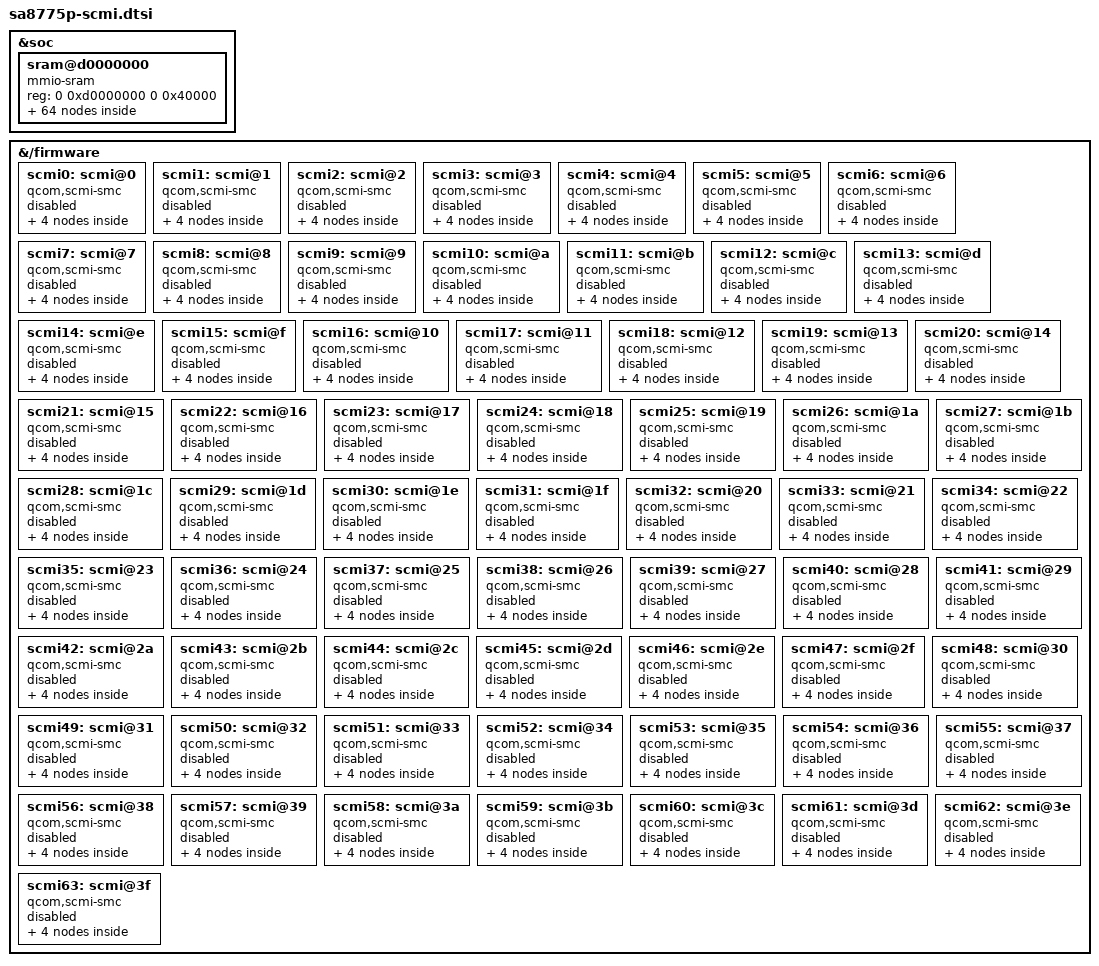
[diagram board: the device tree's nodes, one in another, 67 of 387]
/*
 * Copyright (c) 2023 Qualcomm Innovation Center, Inc. All rights reserved.
 * SPDX-License-Identifier: BSD-3-Clause
 */

&soc {
	sram@d0000000 {
		#address-cells = <2>;
		#size-cells = <2>;
		compatible = "mmio-sram";
		reg = <0 0xd0000000 0 0x40000>;
		ranges;

		shmem0: scmi-sram@d0000000 {
			compatible = "arm,scmi-shmem";
			reg = <0 0xd0000000 0 0x1000>;
		};

		shmem1: scmi-sram@d0001000 {
			compatible = "arm,scmi-shmem";
			reg = <0 0xd0001000 0 0x1000>;
		};

		shmem2: scmi-sram@d0002000 {
			compatible = "arm,scmi-shmem";
			reg = <0 0xd0002000 0 0x1000>;
		};

		shmem3: scmi-sram@d0003000 {
			compatible = "arm,scmi-shmem";
			reg = <0 0xd0003000 0 0x1000>;
		};

		shmem4: scmi-sram@d0004000 {
			compatible = "arm,scmi-shmem";
			reg = <0 0xd0004000 0 0x1000>;
		};

		shmem5: scmi-sram@d0005000 {
			compatible = "arm,scmi-shmem";
			reg = <0 0xd0005000 0 0x1000>;
		};

		shmem6: scmi-sram@d0006000 {
			compatible = "arm,scmi-shmem";
			reg = <0 0xd0006000 0 0x1000>;
		};

		shmem7: scmi-sram@d0007000 {
			compatible = "arm,scmi-shmem";
			reg = <0 0xd0007000 0 0x1000>;
		};

		shmem8: scmi-sram@d0008000 {
			compatible = "arm,scmi-shmem";
			reg = <0 0xd0008000 0 0x1000>;
		};

		shmem9: scmi-sram@d0009000 {
			compatible = "arm,scmi-shmem";
			reg = <0 0xd0009000 0 0x1000>;
		};

		shmem10: scmi-sram@d000a000 {
			compatible = "arm,scmi-shmem";
			reg = <0 0xd000a000 0 0x1000>;
		};

		shmem11: scmi-sram@d000b000 {
			compatible = "arm,scmi-shmem";
			reg = <0 0xd000b000 0 0x1000>;
		};

		shmem12: scmi-sram@d000c000 {
			compatible = "arm,scmi-shmem";
			reg = <0 0xd000c000 0 0x1000>;
		};

		shmem13: scmi-sram@d000d000 {
			compatible = "arm,scmi-shmem";
			reg = <0 0xd000d000 0 0x1000>;
		};

		shmem14: scmi-sram@d000e000 {
			compatible = "arm,scmi-shmem";
			reg = <0 0xd000e000 0 0x1000>;
		};

		shmem15: scmi-sram@d000f000 {
			compatible = "arm,scmi-shmem";
			reg = <0 0xd000f000 0 0x1000>;
		};

		shmem16: scmi-sram@d0010000 {
			compatible = "arm,scmi-shmem";
			reg = <0 0xd0010000 0 0x1000>;
		};

		shmem17: scmi-sram@d0011000 {
			compatible = "arm,scmi-shmem";
			reg = <0 0xd0011000 0 0x1000>;
		};

		shmem18: scmi-sram@d0012000 {
			compatible = "arm,scmi-shmem";
			reg = <0 0xd0012000 0 0x1000>;
		};

		shmem19: scmi-sram@d0013000 {
			compatible = "arm,scmi-shmem";
			reg = <0 0xd0013000 0 0x1000>;
		};

		shmem20: scmi-sram@d0014000 {
			compatible = "arm,scmi-shmem";
			reg = <0 0xd0014000 0 0x1000>;
		};

		shmem21: scmi-sram@d0015000 {
			compatible = "arm,scmi-shmem";
			reg = <0 0xd0015000 0 0x1000>;
		};

		shmem22: scmi-sram@d0016000 {
			compatible = "arm,scmi-shmem";
			reg = <0 0xd0016000 0 0x1000>;
		};

		shmem23: scmi-sram@d0017000 {
			compatible = "arm,scmi-shmem";
			reg = <0 0xd0017000 0 0x1000>;
		};

		shmem24: scmi-sram@d0018000 {
			compatible = "arm,scmi-shmem";
			reg = <0 0xd0018000 0 0x1000>;
		};

		shmem25: scmi-sram@d0019000 {
			compatible = "arm,scmi-shmem";
			reg = <0 0xd0019000 0 0x1000>;
		};

		shmem26: scmi-sram@d001a000 {
			compatible = "arm,scmi-shmem";
			reg = <0 0xd001a000 0 0x1000>;
		};

		shmem27: scmi-sram@d001b000 {
			compatible = "arm,scmi-shmem";
			reg = <0 0xd001b000 0 0x1000>;
		};

		shmem28: scmi-sram@d001c000 {
			compatible = "arm,scmi-shmem";
			reg = <0 0xd001c000 0 0x1000>;
		};

		shmem29: scmi-sram@d001d000 {
			compatible = "arm,scmi-shmem";
			reg = <0 0xd001d000 0 0x1000>;
		};

		shmem30: scmi-sram@d001e000 {
			compatible = "arm,scmi-shmem";
			reg = <0 0xd001e000 0 0x1000>;
		};

		shmem31: scmi-sram@d001f000 {
			compatible = "arm,scmi-shmem";
			reg = <0 0xd001f000 0 0x1000>;
		};

		shmem32: scmi-sram@d0020000 {
			compatible = "arm,scmi-shmem";
			reg = <0 0xd0020000 0 0x1000>;
		};

		shmem33: scmi-sram@d0021000 {
			compatible = "arm,scmi-shmem";
			reg = <0 0xd0021000 0 0x1000>;
		};

		shmem34: scmi-sram@d0022000 {
			compatible = "arm,scmi-shmem";
			reg = <0 0xd0022000 0 0x1000>;
		};

		shmem35: scmi-sram@d0023000 {
			compatible = "arm,scmi-shmem";
			reg = <0 0xd0023000 0 0x1000>;
		};

		shmem36: scmi-sram@d0024000 {
			compatible = "arm,scmi-shmem";
			reg = <0 0xd0024000 0 0x1000>;
		};

		shmem37: scmi-sram@d0025000 {
			compatible = "arm,scmi-shmem";
			reg = <0 0xd0025000 0 0x1000>;
		};

		shmem38: scmi-sram@d0026000 {
			compatible = "arm,scmi-shmem";
			reg = <0 0xd0026000 0 0x1000>;
		};

		shmem39: scmi-sram@d0027000 {
			compatible = "arm,scmi-shmem";
			reg = <0 0xd0027000 0 0x1000>;
		};

		shmem40: scmi-sram@d0028000 {
			compatible = "arm,scmi-shmem";
			reg = <0 0xd0028000 0 0x1000>;
		};

		shmem41: scmi-sram@d0029000 {
			compatible = "arm,scmi-shmem";
			reg = <0 0xd0029000 0 0x1000>;
		};

		shmem42: scmi-sram@d002a000 {
			compatible = "arm,scmi-shmem";
			reg = <0 0xd002a000 0 0x1000>;
		};

		shmem43: scmi-sram@d002b000 {
			compatible = "arm,scmi-shmem";
			reg = <0 0xd002b000 0 0x1000>;
		};

		shmem44: scmi-sram@d002c000 {
			compatible = "arm,scmi-shmem";
			reg = <0 0xd002c000 0 0x1000>;
		};

		shmem45: scmi-sram@d002d000 {
			compatible = "arm,scmi-shmem";
			reg = <0 0xd002d000 0 0x1000>;
		};

		shmem46: scmi-sram@d002e000 {
			compatible = "arm,scmi-shmem";
			reg = <0 0xd002e000 0 0x1000>;
		};

		shmem47: scmi-sram@d002f000 {
			compatible = "arm,scmi-shmem";
			reg = <0 0xd002f000 0 0x1000>;
		};

		shmem48: scmi-sram@d0030000 {
			compatible = "arm,scmi-shmem";
			reg = <0 0xd0030000 0 0x1000>;
		};

		shmem49: scmi-sram@d0031000 {
			compatible = "arm,scmi-shmem";
			reg = <0 0xd0031000 0 0x1000>;
		};

		shmem50: scmi-sram@d0032000 {
			compatible = "arm,scmi-shmem";
			reg = <0 0xd0032000 0 0x1000>;
		};

		shmem51: scmi-sram@d0033000 {
			compatible = "arm,scmi-shmem";
			reg = <0 0xd0033000 0 0x1000>;
		};

		shmem52: scmi-sram@d0034000 {
			compatible = "arm,scmi-shmem";
			reg = <0 0xd0034000 0 0x1000>;
		};

		shmem53: scmi-sram@d0035000 {
			compatible = "arm,scmi-shmem";
			reg = <0 0xd0035000 0 0x1000>;
		};

		shmem54: scmi-sram@d0036000 {
			compatible = "arm,scmi-shmem";
			reg = <0 0xd0036000 0 0x1000>;
		};

		shmem55: scmi-sram@d0037000 {
			compatible = "arm,scmi-shmem";
			reg = <0 0xd0037000 0 0x1000>;
		};

		shmem56: scmi-sram@d0038000 {
			compatible = "arm,scmi-shmem";
			reg = <0 0xd0038000 0 0x1000>;
		};

		shmem57: scmi-sram@d0039000 {
			compatible = "arm,scmi-shmem";
			reg = <0 0xd0039000 0 0x1000>;
		};

		shmem58: scmi-sram@d003a000 {
			compatible = "arm,scmi-shmem";
			reg = <0 0xd003a000 0 0x1000>;
		};

		shmem59: scmi-sram@d003b000 {
			compatible = "arm,scmi-shmem";
			reg = <0 0xd003b000 0 0x1000>;
		};

		shmem60: scmi-sram@d003c000 {
			compatible = "arm,scmi-shmem";
			reg = <0 0xd003c000 0 0x1000>;
		};

		shmem61: scmi-sram@d003d000 {
			compatible = "arm,scmi-shmem";
			reg = <0 0xd003d000 0 0x1000>;
		};

		shmem62: scmi-sram@d003e000 {
			compatible = "arm,scmi-shmem";
			reg = <0 0xd003e000 0 0x1000>;
		};

		shmem63: scmi-sram@d003f000 {
			compatible = "arm,scmi-shmem";
			reg = <0 0xd003f000 0 0x1000>;
		};
	};
};

&{/firmware} {
	scmi0: scmi@0 {
		compatible = "qcom,scmi-smc";
		arm,smc-id = <0xc6008012>;
		shmem = <&shmem0>;

		interrupts = <GIC_SPI 920 IRQ_TYPE_EDGE_RISING>;
		interrupt-names = "a2p";

		status = "disabled";

		#address-cells = <1>;
		#size-cells = <0>;

		scmi0_pd: protocol@11 {
			reg = <0x11>;
			#power-domain-cells = <1>;
			status = "disabled";
		};

		scmi0_dvfs: protocol@13 {
			reg = <0x13>;
			#power-domain-cells = <1>;
			status = "disabled";
		};

		scmi0_sensor: protocol@15 {
			reg = <0x15>;
			#thermal-sensor-cells = <1>;
			status = "disabled";
		};

		scmi0_rst: protocol@16 {
			reg = <0x16>;
			#reset-cells = <1>;
			status = "disabled";
		};
	};

	scmi1: scmi@1 {
		compatible = "qcom,scmi-smc";
		arm,smc-id = <0xc6008012>;
		shmem = <&shmem1>;

		interrupts = <GIC_SPI 921 IRQ_TYPE_EDGE_RISING>;
		interrupt-names = "a2p";

		status = "disabled";

		#address-cells = <1>;
		#size-cells = <0>;

		scmi1_pd: protocol@11 {
			reg = <0x11>;
			#power-domain-cells = <1>;
			status = "disabled";
		};

		scmi1_dvfs: protocol@13 {
			reg = <0x13>;
			#power-domain-cells = <1>;
			status = "disabled";
		};

		scmi1_sensor: protocol@15 {
			reg = <0x15>;
			#thermal-sensor-cells = <1>;
			status = "disabled";
		};

		scmi1_rst: protocol@16 {
			reg = <0x16>;
			#reset-cells = <1>;
			status = "disabled";
		};
	};

	scmi2: scmi@2 {
		compatible = "qcom,scmi-smc";
		arm,smc-id = <0xc6008012>;
		shmem = <&shmem2>;

		interrupts = <GIC_SPI 922 IRQ_TYPE_EDGE_RISING>;
		interrupt-names = "a2p";

		status = "disabled";

		#address-cells = <1>;
		#size-cells = <0>;

		scmi2_pd: protocol@11 {
			reg = <0x11>;
			#power-domain-cells = <1>;
			status = "disabled";
		};

		scmi2_dvfs: protocol@13 {
			reg = <0x13>;
			#power-domain-cells = <1>;
			status = "disabled";
		};

		scmi2_sensor: protocol@15 {
			reg = <0x15>;
			#thermal-sensor-cells = <1>;
			status = "disabled";
		};

		scmi2_rst: protocol@16 {
			reg = <0x16>;
			#reset-cells = <1>;
			status = "disabled";
		};
	};

	scmi3: scmi@3 {
		compatible = "qcom,scmi-smc";
		arm,smc-id = <0xc6008012>;
		shmem = <&shmem3>;

		interrupts = <GIC_SPI 923 IRQ_TYPE_EDGE_RISING>;
		interrupt-names = "a2p";

		status = "disabled";

		#address-cells = <1>;
		#size-cells = <0>;

		scmi3_pd: protocol@11 {
			reg = <0x11>;
			#power-domain-cells = <1>;
			status = "disabled";
		};

		scmi3_dvfs: protocol@13 {
			reg = <0x13>;
			#power-domain-cells = <1>;
			status = "disabled";
		};

		scmi3_sensor: protocol@15 {
			reg = <0x15>;
			#thermal-sensor-cells = <1>;
			status = "disabled";
		};

		scmi3_rst: protocol@16 {
			reg = <0x16>;
			#reset-cells = <1>;
			status = "disabled";
		};
	};

	scmi4: scmi@4 {
		compatible = "qcom,scmi-smc";
		arm,smc-id = <0xc6008012>;
		shmem = <&shmem4>;

		interrupts = <GIC_SPI 924 IRQ_TYPE_EDGE_RISING>;
		interrupt-names = "a2p";

		status = "disabled";

		#address-cells = <1>;
		#size-cells = <0>;

		scmi4_pd: protocol@11 {
			reg = <0x11>;
			#power-domain-cells = <1>;
			status = "disabled";
		};

		scmi4_dvfs: protocol@13 {
			reg = <0x13>;
			#power-domain-cells = <1>;
			status = "disabled";
		};

		scmi4_sensor: protocol@15 {
			reg = <0x15>;
			#thermal-sensor-cells = <1>;
			status = "disabled";
		};

		scmi4_rst: protocol@16 {
			reg = <0x16>;
			#reset-cells = <1>;
			status = "disabled";
		};
	};

	scmi5: scmi@5 {
		compatible = "qcom,scmi-smc";
		arm,smc-id = <0xc6008012>;
		shmem = <&shmem5>;

		interrupts = <GIC_SPI 925 IRQ_TYPE_EDGE_RISING>;
		interrupt-names = "a2p";

		status = "disabled";

		#address-cells = <1>;
		#size-cells = <0>;

		scmi5_pd: protocol@11 {
			reg = <0x11>;
			#power-domain-cells = <1>;
			status = "disabled";
		};

		scmi5_dvfs: protocol@13 {
			reg = <0x13>;
			#power-domain-cells = <1>;
			status = "disabled";
		};

		scmi5_sensor: protocol@15 {
			reg = <0x15>;
			#thermal-sensor-cells = <1>;
			status = "disabled";
		};

		scmi5_rst: protocol@16 {
			reg = <0x16>;
			#reset-cells = <1>;
			status = "disabled";
		};
	};

	scmi6: scmi@6 {
		compatible = "qcom,scmi-smc";
		arm,smc-id = <0xc6008012>;
		shmem = <&shmem6>;

		interrupts = <GIC_SPI 926 IRQ_TYPE_EDGE_RISING>;
		interrupt-names = "a2p";

		status = "disabled";

		#address-cells = <1>;
		#size-cells = <0>;

		scmi6_pd: protocol@11 {
			reg = <0x11>;
			#power-domain-cells = <1>;
			status = "disabled";
		};

		scmi6_dvfs: protocol@13 {
			reg = <0x13>;
			#power-domain-cells = <1>;
			status = "disabled";
		};

		scmi6_sensor: protocol@15 {
			reg = <0x15>;
			#thermal-sensor-cells = <1>;
			status = "disabled";
		};

		scmi6_rst: protocol@16 {
			reg = <0x16>;
			#reset-cells = <1>;
			status = "disabled";
		};
	};

	scmi7: scmi@7 {
		compatible = "qcom,scmi-smc";
		arm,smc-id = <0xc6008012>;
		shmem = <&shmem7>;

		interrupts = <GIC_SPI 927 IRQ_TYPE_EDGE_RISING>;
		interrupt-names = "a2p";

		status = "disabled";

		#address-cells = <1>;
		#size-cells = <0>;

		scmi7_pd: protocol@11 {
			reg = <0x11>;
			#power-domain-cells = <1>;
			status = "disabled";
		};

		scmi7_dvfs: protocol@13 {
			reg = <0x13>;
			#power-domain-cells = <1>;
			status = "disabled";
		};

		scmi7_sensor: protocol@15 {
			reg = <0x15>;
			#thermal-sensor-cells = <1>;
			status = "disabled";
		};

		scmi7_rst: protocol@16 {
			reg = <0x16>;
			#reset-cells = <1>;
			status = "disabled";
		};
	};

	scmi8: scmi@8 {
		compatible = "qcom,scmi-smc";
		arm,smc-id = <0xc6008012>;
		shmem = <&shmem8>;

		interrupts = <GIC_SPI 928 IRQ_TYPE_EDGE_RISING>;
		interrupt-names = "a2p";

		status = "disabled";

		#address-cells = <1>;
		#size-cells = <0>;

		scmi8_pd: protocol@11 {
			reg = <0x11>;
			#power-domain-cells = <1>;
			status = "disabled";
		};

		scmi8_dvfs: protocol@13 {
			reg = <0x13>;
			#power-domain-cells = <1>;
			status = "disabled";
		};

		scmi8_sensor: protocol@15 {
			reg = <0x15>;
			#thermal-sensor-cells = <1>;
			status = "disabled";
		};

		scmi8_rst: protocol@16 {
			reg = <0x16>;
			#reset-cells = <1>;
			status = "disabled";
		};
	};

	scmi9: scmi@9 {
		compatible = "qcom,scmi-smc";
		arm,smc-id = <0xc6008012>;
		shmem = <&shmem9>;

		interrupts = <GIC_SPI 929 IRQ_TYPE_EDGE_RISING>;
		interrupt-names = "a2p";

		status = "disabled";

		#address-cells = <1>;
		#size-cells = <0>;

		scmi9_pd: protocol@11 {
			reg = <0x11>;
			#power-domain-cells = <1>;
			status = "disabled";
		};

		scmi9_dvfs: protocol@13 {
			reg = <0x13>;
			#power-domain-cells = <1>;
			status = "disabled";
		};

		scmi9_sensor: protocol@15 {
			reg = <0x15>;
			#thermal-sensor-cells = <1>;
			status = "disabled";
		};

		scmi9_rst: protocol@16 {
			reg = <0x16>;
			#reset-cells = <1>;
			status = "disabled";
		};
	};

	scmi10: scmi@a {
		compatible = "qcom,scmi-smc";
		arm,smc-id = <0xc6008012>;
		shmem = <&shmem10>;

		interrupts = <GIC_SPI 930 IRQ_TYPE_EDGE_RISING>;
		interrupt-names = "a2p";

		status = "disabled";

		#address-cells = <1>;
		#size-cells = <0>;

		scmi10_pd: protocol@11 {
			reg = <0x11>;
			#power-domain-cells = <1>;
			status = "disabled";
		};

		scmi10_dvfs: protocol@13 {
			reg = <0x13>;
			#power-domain-cells = <1>;
			status = "disabled";
		};

		scmi10_sensor: protocol@15 {
			reg = <0x15>;
			#thermal-sensor-cells = <1>;
			status = "disabled";
		};

		scmi10_rst: protocol@16 {
			reg = <0x16>;
			#reset-cells = <1>;
			status = "disabled";
		};
	};

	scmi11: scmi@b {
		compatible = "qcom,scmi-smc";
		arm,smc-id = <0xc6008012>;
		shmem = <&shmem11>;

		interrupts = <GIC_SPI 931 IRQ_TYPE_EDGE_RISING>;
		interrupt-names = "a2p";

		status = "disabled";

		#address-cells = <1>;
		#size-cells = <0>;

		scmi11_pd: protocol@11 {
			reg = <0x11>;
			#power-domain-cells = <1>;
			status = "disabled";
		};

		scmi11_dvfs: protocol@13 {
			reg = <0x13>;
			#power-domain-cells = <1>;
			status = "disabled";
		};

		scmi11_sensor: protocol@15 {
			reg = <0x15>;
			#thermal-sensor-cells = <1>;
			status = "disabled";
		};

		scmi11_rst: protocol@16 {
			reg = <0x16>;
			#reset-cells = <1>;
			status = "disabled";
		};
	};

	scmi12: scmi@c {
		compatible = "qcom,scmi-smc";
		arm,smc-id = <0xc6008012>;
		shmem = <&shmem12>;

		interrupts = <GIC_SPI 932 IRQ_TYPE_EDGE_RISING>;
		interrupt-names = "a2p";

		status = "disabled";

		#address-cells = <1>;
		#size-cells = <0>;

		scmi12_pd: protocol@11 {
			reg = <0x11>;
			#power-domain-cells = <1>;
			status = "disabled";
		};

		scmi12_dvfs: protocol@13 {
			reg = <0x13>;
			#power-domain-cells = <1>;
			status = "disabled";
		};

		scmi12_sensor: protocol@15 {
			reg = <0x15>;
			#thermal-sensor-cells = <1>;
			status = "disabled";
		};

		scmi12_rst: protocol@16 {
			reg = <0x16>;
			#reset-cells = <1>;
			status = "disabled";
		};
	};

	scmi13: scmi@d {
		compatible = "qcom,scmi-smc";
		arm,smc-id = <0xc6008012>;
		shmem = <&shmem13>;

		interrupts = <GIC_SPI 933 IRQ_TYPE_EDGE_RISING>;
		interrupt-names = "a2p";

		status = "disabled";

		#address-cells = <1>;
		#size-cells = <0>;

		scmi13_pd: protocol@11 {
			reg = <0x11>;
			#power-domain-cells = <1>;
			status = "disabled";
		};

		scmi13_dvfs: protocol@13 {
			reg = <0x13>;
			#power-domain-cells = <1>;
			status = "disabled";
		};

		scmi13_sensor: protocol@15 {
			reg = <0x15>;
			#thermal-sensor-cells = <1>;
			status = "disabled";
		};

		scmi13_rst: protocol@16 {
			reg = <0x16>;
			#reset-cells = <1>;
			status = "disabled";
		};
	};

	scmi14: scmi@e {
		compatible = "qcom,scmi-smc";
		arm,smc-id = <0xc6008012>;
		shmem = <&shmem14>;

		interrupts = <GIC_SPI 934 IRQ_TYPE_EDGE_RISING>;
		interrupt-names = "a2p";

		status = "disabled";

		#address-cells = <1>;
		#size-cells = <0>;

		scmi14_pd: protocol@11 {
			reg = <0x11>;
			#power-domain-cells = <1>;
			status = "disabled";
		};

		scmi14_dvfs: protocol@13 {
			reg = <0x13>;
			#power-domain-cells = <1>;
			status = "disabled";
		};

		scmi14_sensor: protocol@15 {
			reg = <0x15>;
			#thermal-sensor-cells = <1>;
			status = "disabled";
		};

		scmi14_rst: protocol@16 {
			reg = <0x16>;
			#reset-cells = <1>;
			status = "disabled";
		};
	};

	scmi15: scmi@f {
		compatible = "qcom,scmi-smc";
		arm,smc-id = <0xc6008012>;
		shmem = <&shmem15>;

		interrupts = <GIC_SPI 935 IRQ_TYPE_EDGE_RISING>;
		interrupt-names = "a2p";

		status = "disabled";

		#address-cells = <1>;
		#size-cells = <0>;

		scmi15_pd: protocol@11 {
			reg = <0x11>;
			#power-domain-cells = <1>;
			status = "disabled";
		};

		scmi15_dvfs: protocol@13 {
			reg = <0x13>;
			#power-domain-cells = <1>;
			status = "disabled";
		};

		scmi15_sensor: protocol@15 {
			reg = <0x15>;
			#thermal-sensor-cells = <1>;
			status = "disabled";
		};

		scmi15_rst: protocol@16 {
			reg = <0x16>;
			#reset-cells = <1>;
			status = "disabled";
		};
	};

	scmi16: scmi@10 {
		compatible = "qcom,scmi-smc";
		arm,smc-id = <0xc6008012>;
		shmem = <&shmem16>;

		interrupts = <GIC_SPI 936 IRQ_TYPE_EDGE_RISING>;
		interrupt-names = "a2p";

		status = "disabled";

		#address-cells = <1>;
		#size-cells = <0>;

		scmi16_pd: protocol@11 {
			reg = <0x11>;
			#power-domain-cells = <1>;
			status = "disabled";
		};

		scmi16_dvfs: protocol@13 {
			reg = <0x13>;
			#power-domain-cells = <1>;
			status = "disabled";
		};

		scmi16_sensor: protocol@15 {
			reg = <0x15>;
			#thermal-sensor-cells = <1>;
			status = "disabled";
		};

		scmi16_rst: protocol@16 {
			reg = <0x16>;
			#reset-cells = <1>;
			status = "disabled";
		};
	};

	scmi17: scmi@11 {
		compatible = "qcom,scmi-smc";
		arm,smc-id = <0xc6008012>;
		shmem = <&shmem17>;

		interrupts = <GIC_SPI 937 IRQ_TYPE_EDGE_RISING>;
		interrupt-names = "a2p";

		status = "disabled";

		#address-cells = <1>;
		#size-cells = <0>;

		scmi17_pd: protocol@11 {
			reg = <0x11>;
			#power-domain-cells = <1>;
			status = "disabled";
		};

		scmi17_dvfs: protocol@13 {
			reg = <0x13>;
			#power-domain-cells = <1>;
			status = "disabled";
		};

		scmi17_sensor: protocol@15 {
			reg = <0x15>;
			#thermal-sensor-cells = <1>;
			status = "disabled";
		};

		scmi17_rst: protocol@16 {
			reg = <0x16>;
			#reset-cells = <1>;
			status = "disabled";
		};
	};

	scmi18: scmi@12 {
		compatible = "qcom,scmi-smc";
		arm,smc-id = <0xc6008012>;
		shmem = <&shmem18>;

		interrupts = <GIC_SPI 938 IRQ_TYPE_EDGE_RISING>;
		interrupt-names = "a2p";

		status = "disabled";

		#address-cells = <1>;
		#size-cells = <0>;

		scmi18_pd: protocol@11 {
			reg = <0x11>;
			#power-domain-cells = <1>;
			status = "disabled";
		};

		scmi18_dvfs: protocol@13 {
			reg = <0x13>;
			#power-domain-cells = <1>;
			status = "disabled";
		};

		scmi18_sensor: protocol@15 {
			reg = <0x15>;
			#thermal-sensor-cells = <1>;
			status = "disabled";
		};

		scmi18_rst: protocol@16 {
			reg = <0x16>;
			#reset-cells = <1>;
			status = "disabled";
		};
	};

	scmi19: scmi@13 {
		compatible = "qcom,scmi-smc";
		arm,smc-id = <0xc6008012>;
		shmem = <&shmem19>;

		interrupts = <GIC_SPI 939 IRQ_TYPE_EDGE_RISING>;
		interrupt-names = "a2p";

		status = "disabled";

		#address-cells = <1>;
		#size-cells = <0>;

		scmi19_pd: protocol@11 {
			reg = <0x11>;
			#power-domain-cells = <1>;
			status = "disabled";
		};

		scmi19_dvfs: protocol@13 {
			reg = <0x13>;
			#power-domain-cells = <1>;
			status = "disabled";
		};

		scmi19_sensor: protocol@15 {
			reg = <0x15>;
			#thermal-sensor-cells = <1>;
			status = "disabled";
		};

		scmi19_rst: protocol@16 {
			reg = <0x16>;
			#reset-cells = <1>;
			status = "disabled";
		};
	};

	scmi20: scmi@14 {
		compatible = "qcom,scmi-smc";
		arm,smc-id = <0xc6008012>;
		shmem = <&shmem20>;

		interrupts = <GIC_SPI 940 IRQ_TYPE_EDGE_RISING>;
		interrupt-names = "a2p";

		status = "disabled";

		#address-cells = <1>;
		#size-cells = <0>;

		scmi20_pd: protocol@11 {
			reg = <0x11>;
			#power-domain-cells = <1>;
			status = "disabled";
		};

		scmi20_dvfs: protocol@13 {
			reg = <0x13>;
			#power-domain-cells = <1>;
			status = "disabled";
		};

		scmi20_sensor: protocol@15 {
			reg = <0x15>;
			#thermal-sensor-cells = <1>;
			status = "disabled";
		};

		scmi20_rst: protocol@16 {
			reg = <0x16>;
			#reset-cells = <1>;
			status = "disabled";
		};
	};

	scmi21: scmi@15 {
		compatible = "qcom,scmi-smc";
		arm,smc-id = <0xc6008012>;
		shmem = <&shmem21>;

		interrupts = <GIC_SPI 941 IRQ_TYPE_EDGE_RISING>;
		interrupt-names = "a2p";

		status = "disabled";

		#address-cells = <1>;
		#size-cells = <0>;

		scmi21_pd: protocol@11 {
			reg = <0x11>;
			#power-domain-cells = <1>;
			status = "disabled";
		};

		scmi21_dvfs: protocol@13 {
			reg = <0x13>;
			#power-domain-cells = <1>;
			status = "disabled";
		};

		scmi21_sensor: protocol@15 {
			reg = <0x15>;
			#thermal-sensor-cells = <1>;
			status = "disabled";
		};

		scmi21_rst: protocol@16 {
			reg = <0x16>;
			#reset-cells = <1>;
			status = "disabled";
		};
	};

	scmi22: scmi@16 {
		compatible = "qcom,scmi-smc";
		arm,smc-id = <0xc6008012>;
		shmem = <&shmem22>;

		interrupts = <GIC_SPI 942 IRQ_TYPE_EDGE_RISING>;
		interrupt-names = "a2p";

		status = "disabled";

		#address-cells = <1>;
		#size-cells = <0>;

		scmi22_pd: protocol@11 {
			reg = <0x11>;
			#power-domain-cells = <1>;
			status = "disabled";
		};

		scmi22_dvfs: protocol@13 {
			reg = <0x13>;
			#power-domain-cells = <1>;
			status = "disabled";
		};

		scmi22_sensor: protocol@15 {
			reg = <0x15>;
			#thermal-sensor-cells = <1>;
			status = "disabled";
		};

		scmi22_rst: protocol@16 {
			reg = <0x16>;
			#reset-cells = <1>;
			status = "disabled";
		};
	};

	scmi23: scmi@17 {
		compatible = "qcom,scmi-smc";
		arm,smc-id = <0xc6008012>;
		shmem = <&shmem23>;

		interrupts = <GIC_SPI 943 IRQ_TYPE_EDGE_RISING>;
		interrupt-names = "a2p";

		status = "disabled";

		#address-cells = <1>;
		#size-cells = <0>;

		scmi23_pd: protocol@11 {
			reg = <0x11>;
			#power-domain-cells = <1>;
			status = "disabled";
		};

		scmi23_dvfs: protocol@13 {
			reg = <0x13>;
			#power-domain-cells = <1>;
			status = "disabled";
		};

		scmi23_sensor: protocol@15 {
			reg = <0x15>;
			#thermal-sensor-cells = <1>;
			status = "disabled";
		};

		scmi23_rst: protocol@16 {
			reg = <0x16>;
			#reset-cells = <1>;
			status = "disabled";
		};
	};

	scmi24: scmi@18 {
		compatible = "qcom,scmi-smc";
		arm,smc-id = <0xc6008012>;
		shmem = <&shmem24>;

		interrupts = <GIC_SPI 944 IRQ_TYPE_EDGE_RISING>;
		interrupt-names = "a2p";

		status = "disabled";

		#address-cells = <1>;
		#size-cells = <0>;

		scmi24_pd: protocol@11 {
			reg = <0x11>;
			#power-domain-cells = <1>;
			status = "disabled";
		};

		scmi24_dvfs: protocol@13 {
			reg = <0x13>;
			#power-domain-cells = <1>;
			status = "disabled";
		};

		scmi24_sensor: protocol@15 {
			reg = <0x15>;
			#thermal-sensor-cells = <1>;
			status = "disabled";
		};

		scmi24_rst: protocol@16 {
			reg = <0x16>;
			#reset-cells = <1>;
			status = "disabled";
		};
	};

	scmi25: scmi@19 {
		compatible = "qcom,scmi-smc";
		arm,smc-id = <0xc6008012>;
		shmem = <&shmem25>;

		interrupts = <GIC_SPI 945 IRQ_TYPE_EDGE_RISING>;
		interrupt-names = "a2p";

		status = "disabled";

		#address-cells = <1>;
		#size-cells = <0>;

		scmi25_pd: protocol@11 {
			reg = <0x11>;
			#power-domain-cells = <1>;
			status = "disabled";
		};

		scmi25_dvfs: protocol@13 {
			reg = <0x13>;
			#power-domain-cells = <1>;
			status = "disabled";
		};

		scmi25_sensor: protocol@15 {
			reg = <0x15>;
			#thermal-sensor-cells = <1>;
			status = "disabled";
		};

		scmi25_rst: protocol@16 {
			reg = <0x16>;
			#reset-cells = <1>;
			status = "disabled";
		};
	};

	scmi26: scmi@1a {
		compatible = "qcom,scmi-smc";
		arm,smc-id = <0xc6008012>;
		shmem = <&shmem26>;

		interrupts = <GIC_SPI 946 IRQ_TYPE_EDGE_RISING>;
		interrupt-names = "a2p";

		status = "disabled";

		#address-cells = <1>;
		#size-cells = <0>;

		scmi26_pd: protocol@11 {
			reg = <0x11>;
			#power-domain-cells = <1>;
			status = "disabled";
		};

		scmi26_dvfs: protocol@13 {
			reg = <0x13>;
			#power-domain-cells = <1>;
			status = "disabled";
		};

		scmi26_sensor: protocol@15 {
			reg = <0x15>;
			#thermal-sensor-cells = <1>;
			status = "disabled";
		};

		scmi26_rst: protocol@16 {
			reg = <0x16>;
			#reset-cells = <1>;
			status = "disabled";
		};
	};

	scmi27: scmi@1b {
		compatible = "qcom,scmi-smc";
		arm,smc-id = <0xc6008012>;
		shmem = <&shmem27>;

		interrupts = <GIC_SPI 947 IRQ_TYPE_EDGE_RISING>;
		interrupt-names = "a2p";

		status = "disabled";

		#address-cells = <1>;
		#size-cells = <0>;

		scmi27_pd: protocol@11 {
			reg = <0x11>;
			#power-domain-cells = <1>;
			status = "disabled";
		};

		scmi27_dvfs: protocol@13 {
			reg = <0x13>;
			#power-domain-cells = <1>;
			status = "disabled";
		};

		scmi27_sensor: protocol@15 {
			reg = <0x15>;
			#thermal-sensor-cells = <1>;
			status = "disabled";
		};

		scmi27_rst: protocol@16 {
			reg = <0x16>;
			#reset-cells = <1>;
			status = "disabled";
		};
	};

	scmi28: scmi@1c {
		compatible = "qcom,scmi-smc";
		arm,smc-id = <0xc6008012>;
		shmem = <&shmem28>;

		interrupts = <GIC_SPI 948 IRQ_TYPE_EDGE_RISING>;
		interrupt-names = "a2p";

		status = "disabled";

		#address-cells = <1>;
		#size-cells = <0>;

		scmi28_pd: protocol@11 {
			reg = <0x11>;
			#power-domain-cells = <1>;
			status = "disabled";
		};

		scmi28_dvfs: protocol@13 {
			reg = <0x13>;
			#power-domain-cells = <1>;
			status = "disabled";
		};

		scmi28_sensor: protocol@15 {
			reg = <0x15>;
			#thermal-sensor-cells = <1>;
			status = "disabled";
		};

		scmi28_rst: protocol@16 {
			reg = <0x16>;
			#reset-cells = <1>;
			status = "disabled";
		};
	};

	scmi29: scmi@1d {
		compatible = "qcom,scmi-smc";
		arm,smc-id = <0xc6008012>;
		shmem = <&shmem29>;

		interrupts = <GIC_SPI 949 IRQ_TYPE_EDGE_RISING>;
		interrupt-names = "a2p";

		status = "disabled";

		#address-cells = <1>;
		#size-cells = <0>;

		scmi29_pd: protocol@11 {
			reg = <0x11>;
			#power-domain-cells = <1>;
			status = "disabled";
		};

		scmi29_dvfs: protocol@13 {
			reg = <0x13>;
			#power-domain-cells = <1>;
			status = "disabled";
		};

		scmi29_sensor: protocol@15 {
			reg = <0x15>;
			#thermal-sensor-cells = <1>;
			status = "disabled";
		};

		scmi29_rst: protocol@16 {
			reg = <0x16>;
			#reset-cells = <1>;
			status = "disabled";
		};
	};

	scmi30: scmi@1e {
		compatible = "qcom,scmi-smc";
		arm,smc-id = <0xc6008012>;
		shmem = <&shmem30>;

		interrupts = <GIC_SPI 950 IRQ_TYPE_EDGE_RISING>;
		interrupt-names = "a2p";

		status = "disabled";

		#address-cells = <1>;
		#size-cells = <0>;

		scmi30_pd: protocol@11 {
			reg = <0x11>;
			#power-domain-cells = <1>;
			status = "disabled";
		};

		scmi30_dvfs: protocol@13 {
			reg = <0x13>;
			#power-domain-cells = <1>;
			status = "disabled";
		};

		scmi30_sensor: protocol@15 {
			reg = <0x15>;
			#thermal-sensor-cells = <1>;
			status = "disabled";
		};

		scmi30_rst: protocol@16 {
			reg = <0x16>;
			#reset-cells = <1>;
			status = "disabled";
		};
	};

	scmi31: scmi@1f {
		compatible = "qcom,scmi-smc";
		arm,smc-id = <0xc6008012>;
		shmem = <&shmem31>;

		interrupts = <GIC_SPI 951 IRQ_TYPE_EDGE_RISING>;
		interrupt-names = "a2p";

		status = "disabled";

		#address-cells = <1>;
		#size-cells = <0>;

		scmi31_pd: protocol@11 {
			reg = <0x11>;
			#power-domain-cells = <1>;
			status = "disabled";
		};

		scmi31_dvfs: protocol@13 {
			reg = <0x13>;
			#power-domain-cells = <1>;
			status = "disabled";
		};

		scmi31_sensor: protocol@15 {
			reg = <0x15>;
			#thermal-sensor-cells = <1>;
			status = "disabled";
		};

		scmi31_rst: protocol@16 {
			reg = <0x16>;
			#reset-cells = <1>;
			status = "disabled";
		};
	};

	scmi32: scmi@20 {
		compatible = "qcom,scmi-smc";
		arm,smc-id = <0xc6008012>;
		shmem = <&shmem32>;

		interrupts = <GIC_SPI 952 IRQ_TYPE_EDGE_RISING>;
		interrupt-names = "a2p";

		status = "disabled";

		#address-cells = <1>;
		#size-cells = <0>;

		scmi32_pd: protocol@11 {
			reg = <0x11>;
			#power-domain-cells = <1>;
			status = "disabled";
		};

		scmi32_dvfs: protocol@13 {
			reg = <0x13>;
			#power-domain-cells = <1>;
			status = "disabled";
		};

		scmi32_sensor: protocol@15 {
			reg = <0x15>;
			#thermal-sensor-cells = <1>;
			status = "disabled";
		};

		scmi32_rst: protocol@16 {
			reg = <0x16>;
			#reset-cells = <1>;
			status = "disabled";
		};
	};

	scmi33: scmi@21 {
		compatible = "qcom,scmi-smc";
		arm,smc-id = <0xc6008012>;
		shmem = <&shmem33>;

		interrupts = <GIC_SPI 953 IRQ_TYPE_EDGE_RISING>;
		interrupt-names = "a2p";

		status = "disabled";

		#address-cells = <1>;
		#size-cells = <0>;

		scmi33_pd: protocol@11 {
			reg = <0x11>;
			#power-domain-cells = <1>;
			status = "disabled";
		};

		scmi33_dvfs: protocol@13 {
			reg = <0x13>;
			#power-domain-cells = <1>;
			status = "disabled";
		};

		scmi33_sensor: protocol@15 {
			reg = <0x15>;
			#thermal-sensor-cells = <1>;
			status = "disabled";
		};

		scmi33_rst: protocol@16 {
			reg = <0x16>;
			#reset-cells = <1>;
			status = "disabled";
		};
	};

	scmi34: scmi@22 {
		compatible = "qcom,scmi-smc";
		arm,smc-id = <0xc6008012>;
		shmem = <&shmem34>;

		interrupts = <GIC_SPI 954 IRQ_TYPE_EDGE_RISING>;
		interrupt-names = "a2p";

		status = "disabled";

		#address-cells = <1>;
		#size-cells = <0>;

		scmi34_pd: protocol@11 {
			reg = <0x11>;
			#power-domain-cells = <1>;
			status = "disabled";
		};

		scmi34_dvfs: protocol@13 {
			reg = <0x13>;
			#power-domain-cells = <1>;
			status = "disabled";
		};

		scmi34_sensor: protocol@15 {
			reg = <0x15>;
			#thermal-sensor-cells = <1>;
			status = "disabled";
		};

		scmi34_rst: protocol@16 {
			reg = <0x16>;
			#reset-cells = <1>;
			status = "disabled";
		};
	};

	scmi35: scmi@23 {
		compatible = "qcom,scmi-smc";
		arm,smc-id = <0xc6008012>;
		shmem = <&shmem35>;

		interrupts = <GIC_SPI 955 IRQ_TYPE_EDGE_RISING>;
		interrupt-names = "a2p";

		status = "disabled";

		#address-cells = <1>;
		#size-cells = <0>;

		scmi35_pd: protocol@11 {
			reg = <0x11>;
			#power-domain-cells = <1>;
			status = "disabled";
		};

		scmi35_dvfs: protocol@13 {
			reg = <0x13>;
			#power-domain-cells = <1>;
			status = "disabled";
		};

		scmi35_sensor: protocol@15 {
			reg = <0x15>;
			#thermal-sensor-cells = <1>;
			status = "disabled";
		};

		scmi35_rst: protocol@16 {
			reg = <0x16>;
			#reset-cells = <1>;
			status = "disabled";
		};
	};

	scmi36: scmi@24 {
		compatible = "qcom,scmi-smc";
		arm,smc-id = <0xc6008012>;
		shmem = <&shmem36>;

		interrupts = <GIC_SPI 956 IRQ_TYPE_EDGE_RISING>;
		interrupt-names = "a2p";

		status = "disabled";

		#address-cells = <1>;
		#size-cells = <0>;

		scmi36_pd: protocol@11 {
			reg = <0x11>;
			#power-domain-cells = <1>;
			status = "disabled";
		};

		scmi36_dvfs: protocol@13 {
			reg = <0x13>;
			#power-domain-cells = <1>;
			status = "disabled";
		};

		scmi36_sensor: protocol@15 {
			reg = <0x15>;
			#thermal-sensor-cells = <1>;
			status = "disabled";
		};

		scmi36_rst: protocol@16 {
			reg = <0x16>;
			#reset-cells = <1>;
			status = "disabled";
		};
	};

	scmi37: scmi@25 {
		compatible = "qcom,scmi-smc";
		arm,smc-id = <0xc6008012>;
		shmem = <&shmem37>;

		interrupts = <GIC_SPI 957 IRQ_TYPE_EDGE_RISING>;
		interrupt-names = "a2p";

		status = "disabled";

		#address-cells = <1>;
		#size-cells = <0>;

		scmi37_pd: protocol@11 {
			reg = <0x11>;
			#power-domain-cells = <1>;
			status = "disabled";
		};

		scmi37_dvfs: protocol@13 {
			reg = <0x13>;
			#power-domain-cells = <1>;
			status = "disabled";
		};

		scmi37_sensor: protocol@15 {
			reg = <0x15>;
			#thermal-sensor-cells = <1>;
			status = "disabled";
		};

		scmi37_rst: protocol@16 {
			reg = <0x16>;
			#reset-cells = <1>;
			status = "disabled";
		};
	};

	scmi38: scmi@26 {
		compatible = "qcom,scmi-smc";
		arm,smc-id = <0xc6008012>;
		shmem = <&shmem38>;

		interrupts = <GIC_SPI 958 IRQ_TYPE_EDGE_RISING>;
		interrupt-names = "a2p";

		status = "disabled";

		#address-cells = <1>;
		#size-cells = <0>;

		scmi38_pd: protocol@11 {
			reg = <0x11>;
			#power-domain-cells = <1>;
			status = "disabled";
		};

		scmi38_dvfs: protocol@13 {
			reg = <0x13>;
			#power-domain-cells = <1>;
			status = "disabled";
		};

		scmi38_sensor: protocol@15 {
			reg = <0x15>;
			#thermal-sensor-cells = <1>;
			status = "disabled";
		};

		scmi38_rst: protocol@16 {
			reg = <0x16>;
			#reset-cells = <1>;
			status = "disabled";
		};
	};

	scmi39: scmi@27 {
		compatible = "qcom,scmi-smc";
		arm,smc-id = <0xc6008012>;
		shmem = <&shmem39>;

		interrupts = <GIC_SPI 959 IRQ_TYPE_EDGE_RISING>;
		interrupt-names = "a2p";

		status = "disabled";

		#address-cells = <1>;
		#size-cells = <0>;

		scmi39_pd: protocol@11 {
			reg = <0x11>;
			#power-domain-cells = <1>;
			status = "disabled";
		};

		scmi39_dvfs: protocol@13 {
			reg = <0x13>;
			#power-domain-cells = <1>;
			status = "disabled";
		};

		scmi39_sensor: protocol@15 {
			reg = <0x15>;
			#thermal-sensor-cells = <1>;
			status = "disabled";
		};

		scmi39_rst: protocol@16 {
			reg = <0x16>;
			#reset-cells = <1>;
			status = "disabled";
		};
	};

	scmi40: scmi@28 {
		compatible = "qcom,scmi-smc";
		arm,smc-id = <0xc6008012>;
		shmem = <&shmem40>;

		interrupts = <GIC_SPI 960 IRQ_TYPE_EDGE_RISING>;
		interrupt-names = "a2p";

		status = "disabled";

		#address-cells = <1>;
		#size-cells = <0>;

		scmi40_pd: protocol@11 {
			reg = <0x11>;
			#power-domain-cells = <1>;
			status = "disabled";
		};

		scmi40_dvfs: protocol@13 {
			reg = <0x13>;
			#power-domain-cells = <1>;
			status = "disabled";
		};

		scmi40_sensor: protocol@15 {
			reg = <0x15>;
			#thermal-sensor-cells = <1>;
			status = "disabled";
		};

		scmi40_rst: protocol@16 {
			reg = <0x16>;
			#reset-cells = <1>;
			status = "disabled";
		};
	};

	scmi41: scmi@29 {
		compatible = "qcom,scmi-smc";
		arm,smc-id = <0xc6008012>;
		shmem = <&shmem41>;

		interrupts = <GIC_SPI 961 IRQ_TYPE_EDGE_RISING>;
		interrupt-names = "a2p";

		status = "disabled";

		#address-cells = <1>;
		#size-cells = <0>;

		scmi41_pd: protocol@11 {
			reg = <0x11>;
			#power-domain-cells = <1>;
			status = "disabled";
		};

		scmi41_dvfs: protocol@13 {
			reg = <0x13>;
			#power-domain-cells = <1>;
			status = "disabled";
		};

		scmi41_sensor: protocol@15 {
			reg = <0x15>;
			#thermal-sensor-cells = <1>;
			status = "disabled";
		};

		scmi41_rst: protocol@16 {
			reg = <0x16>;
			#reset-cells = <1>;
			status = "disabled";
		};
	};

	scmi42: scmi@2a {
		compatible = "qcom,scmi-smc";
		arm,smc-id = <0xc6008012>;
		shmem = <&shmem42>;

		interrupts = <GIC_SPI 962 IRQ_TYPE_EDGE_RISING>;
		interrupt-names = "a2p";

		status = "disabled";

		#address-cells = <1>;
		#size-cells = <0>;

		scmi42_pd: protocol@11 {
			reg = <0x11>;
			#power-domain-cells = <1>;
			status = "disabled";
		};

		scmi42_dvfs: protocol@13 {
			reg = <0x13>;
			#power-domain-cells = <1>;
			status = "disabled";
		};

		scmi42_sensor: protocol@15 {
			reg = <0x15>;
			#thermal-sensor-cells = <1>;
			status = "disabled";
		};

		scmi42_rst: protocol@16 {
			reg = <0x16>;
			#reset-cells = <1>;
			status = "disabled";
		};
	};

	scmi43: scmi@2b {
		compatible = "qcom,scmi-smc";
		arm,smc-id = <0xc6008012>;
		shmem = <&shmem43>;

		interrupts = <GIC_SPI 963 IRQ_TYPE_EDGE_RISING>;
		interrupt-names = "a2p";

		status = "disabled";

		#address-cells = <1>;
		#size-cells = <0>;

		scmi43_pd: protocol@11 {
			reg = <0x11>;
			#power-domain-cells = <1>;
			status = "disabled";
		};

		scmi43_dvfs: protocol@13 {
			reg = <0x13>;
			#power-domain-cells = <1>;
			status = "disabled";
		};

		scmi43_sensor: protocol@15 {
			reg = <0x15>;
			#thermal-sensor-cells = <1>;
			status = "disabled";
		};

		scmi43_rst: protocol@16 {
			reg = <0x16>;
			#reset-cells = <1>;
			status = "disabled";
		};
	};

	scmi44: scmi@2c {
		compatible = "qcom,scmi-smc";
		arm,smc-id = <0xc6008012>;
		shmem = <&shmem44>;

		interrupts = <GIC_SPI 964 IRQ_TYPE_EDGE_RISING>;
		interrupt-names = "a2p";

		status = "disabled";

		#address-cells = <1>;
		#size-cells = <0>;

		scmi44_pd: protocol@11 {
			reg = <0x11>;
			#power-domain-cells = <1>;
			status = "disabled";
		};

		scmi44_dvfs: protocol@13 {
			reg = <0x13>;
			#power-domain-cells = <1>;
			status = "disabled";
		};

		scmi44_sensor: protocol@15 {
			reg = <0x15>;
			#thermal-sensor-cells = <1>;
			status = "disabled";
		};

		scmi44_rst: protocol@16 {
			reg = <0x16>;
			#reset-cells = <1>;
			status = "disabled";
		};
	};

	scmi45: scmi@2d {
		compatible = "qcom,scmi-smc";
		arm,smc-id = <0xc6008012>;
		shmem = <&shmem45>;

		interrupts = <GIC_SPI 965 IRQ_TYPE_EDGE_RISING>;
		interrupt-names = "a2p";

		status = "disabled";

		#address-cells = <1>;
		#size-cells = <0>;

		scmi45_pd: protocol@11 {
			reg = <0x11>;
			#power-domain-cells = <1>;
			status = "disabled";
		};

		scmi45_dvfs: protocol@13 {
			reg = <0x13>;
			#power-domain-cells = <1>;
			status = "disabled";
		};

		scmi45_sensor: protocol@15 {
			reg = <0x15>;
			#thermal-sensor-cells = <1>;
			status = "disabled";
		};

		scmi45_rst: protocol@16 {
			reg = <0x16>;
			#reset-cells = <1>;
			status = "disabled";
		};
	};

	scmi46: scmi@2e {
		compatible = "qcom,scmi-smc";
		arm,smc-id = <0xc6008012>;
		shmem = <&shmem46>;

		interrupts = <GIC_SPI 966 IRQ_TYPE_EDGE_RISING>;
		interrupt-names = "a2p";

		status = "disabled";

		#address-cells = <1>;
		#size-cells = <0>;

		scmi46_pd: protocol@11 {
			reg = <0x11>;
			#power-domain-cells = <1>;
			status = "disabled";
		};

		scmi46_dvfs: protocol@13 {
			reg = <0x13>;
			#power-domain-cells = <1>;
			status = "disabled";
		};

		scmi46_sensor: protocol@15 {
			reg = <0x15>;
			#thermal-sensor-cells = <1>;
			status = "disabled";
		};

		scmi46_rst: protocol@16 {
			reg = <0x16>;
			#reset-cells = <1>;
			status = "disabled";
		};
	};

	scmi47: scmi@2f {
		compatible = "qcom,scmi-smc";
		arm,smc-id = <0xc6008012>;
		shmem = <&shmem47>;

		interrupts = <GIC_SPI 967 IRQ_TYPE_EDGE_RISING>;
		interrupt-names = "a2p";

		status = "disabled";

		#address-cells = <1>;
		#size-cells = <0>;

		scmi47_pd: protocol@11 {
			reg = <0x11>;
			#power-domain-cells = <1>;
			status = "disabled";
		};

		scmi47_dvfs: protocol@13 {
			reg = <0x13>;
			#power-domain-cells = <1>;
			status = "disabled";
		};

		scmi47_sensor: protocol@15 {
			reg = <0x15>;
			#thermal-sensor-cells = <1>;
			status = "disabled";
		};

		scmi47_rst: protocol@16 {
			reg = <0x16>;
			#reset-cells = <1>;
			status = "disabled";
		};
	};

	scmi48: scmi@30 {
		compatible = "qcom,scmi-smc";
		arm,smc-id = <0xc6008012>;
		shmem = <&shmem48>;

		interrupts = <GIC_SPI 968 IRQ_TYPE_EDGE_RISING>;
		interrupt-names = "a2p";

		status = "disabled";

		#address-cells = <1>;
		#size-cells = <0>;

		scmi48_pd: protocol@11 {
			reg = <0x11>;
			#power-domain-cells = <1>;
			status = "disabled";
		};

		scmi48_dvfs: protocol@13 {
			reg = <0x13>;
			#power-domain-cells = <1>;
			status = "disabled";
		};

		scmi48_sensor: protocol@15 {
			reg = <0x15>;
			#thermal-sensor-cells = <1>;
			status = "disabled";
		};

		scmi48_rst: protocol@16 {
			reg = <0x16>;
			#reset-cells = <1>;
			status = "disabled";
		};
	};

	scmi49: scmi@31 {
		compatible = "qcom,scmi-smc";
		arm,smc-id = <0xc6008012>;
		shmem = <&shmem49>;

		interrupts = <GIC_SPI 969 IRQ_TYPE_EDGE_RISING>;
		interrupt-names = "a2p";

		status = "disabled";

		#address-cells = <1>;
		#size-cells = <0>;

		scmi49_pd: protocol@11 {
			reg = <0x11>;
			#power-domain-cells = <1>;
			status = "disabled";
		};

		scmi49_dvfs: protocol@13 {
			reg = <0x13>;
			#power-domain-cells = <1>;
			status = "disabled";
		};

		scmi49_sensor: protocol@15 {
			reg = <0x15>;
			#thermal-sensor-cells = <1>;
			status = "disabled";
		};

		scmi49_rst: protocol@16 {
			reg = <0x16>;
			#reset-cells = <1>;
			status = "disabled";
		};
	};

	scmi50: scmi@32 {
		compatible = "qcom,scmi-smc";
		arm,smc-id = <0xc6008012>;
		shmem = <&shmem50>;

		interrupts = <GIC_SPI 970 IRQ_TYPE_EDGE_RISING>;
		interrupt-names = "a2p";

		status = "disabled";

		#address-cells = <1>;
		#size-cells = <0>;

		scmi50_pd: protocol@11 {
			reg = <0x11>;
			#power-domain-cells = <1>;
			status = "disabled";
		};

		scmi50_dvfs: protocol@13 {
			reg = <0x13>;
			#power-domain-cells = <1>;
			status = "disabled";
		};

		scmi50_sensor: protocol@15 {
			reg = <0x15>;
			#thermal-sensor-cells = <1>;
			status = "disabled";
		};

		scmi50_rst: protocol@16 {
			reg = <0x16>;
			#reset-cells = <1>;
			status = "disabled";
		};
	};

	scmi51: scmi@33 {
		compatible = "qcom,scmi-smc";
		arm,smc-id = <0xc6008012>;
		shmem = <&shmem51>;

		interrupts = <GIC_SPI 971 IRQ_TYPE_EDGE_RISING>;
		interrupt-names = "a2p";

		status = "disabled";

		#address-cells = <1>;
		#size-cells = <0>;

		scmi51_pd: protocol@11 {
			reg = <0x11>;
			#power-domain-cells = <1>;
			status = "disabled";
		};

		scmi51_dvfs: protocol@13 {
			reg = <0x13>;
			#power-domain-cells = <1>;
			status = "disabled";
		};

		scmi51_sensor: protocol@15 {
			reg = <0x15>;
			#thermal-sensor-cells = <1>;
			status = "disabled";
		};

		scmi51_rst: protocol@16 {
			reg = <0x16>;
			#reset-cells = <1>;
			status = "disabled";
		};
	};

	scmi52: scmi@34 {
		compatible = "qcom,scmi-smc";
		arm,smc-id = <0xc6008012>;
		shmem = <&shmem52>;

		interrupts = <GIC_SPI 972 IRQ_TYPE_EDGE_RISING>;
		interrupt-names = "a2p";

		status = "disabled";

		#address-cells = <1>;
		#size-cells = <0>;

		scmi52_pd: protocol@11 {
			reg = <0x11>;
			#power-domain-cells = <1>;
			status = "disabled";
		};

		scmi52_dvfs: protocol@13 {
			reg = <0x13>;
			#power-domain-cells = <1>;
			status = "disabled";
		};

		scmi52_sensor: protocol@15 {
			reg = <0x15>;
			#thermal-sensor-cells = <1>;
			status = "disabled";
		};

		scmi52_rst: protocol@16 {
			reg = <0x16>;
			#reset-cells = <1>;
			status = "disabled";
		};
	};

	scmi53: scmi@35 {
		compatible = "qcom,scmi-smc";
		arm,smc-id = <0xc6008012>;
		shmem = <&shmem53>;

		interrupts = <GIC_SPI 973 IRQ_TYPE_EDGE_RISING>;
		interrupt-names = "a2p";

		status = "disabled";

		#address-cells = <1>;
		#size-cells = <0>;

		scmi53_pd: protocol@11 {
			reg = <0x11>;
			#power-domain-cells = <1>;
			status = "disabled";
		};

		scmi53_dvfs: protocol@13 {
			reg = <0x13>;
			#power-domain-cells = <1>;
			status = "disabled";
		};

		scmi53_sensor: protocol@15 {
			reg = <0x15>;
			#thermal-sensor-cells = <1>;
			status = "disabled";
		};

		scmi53_rst: protocol@16 {
			reg = <0x16>;
			#reset-cells = <1>;
			status = "disabled";
		};
	};

	scmi54: scmi@36 {
		compatible = "qcom,scmi-smc";
		arm,smc-id = <0xc6008012>;
		shmem = <&shmem54>;

		interrupts = <GIC_SPI 974 IRQ_TYPE_EDGE_RISING>;
		interrupt-names = "a2p";

		status = "disabled";

		#address-cells = <1>;
		#size-cells = <0>;

		scmi54_pd: protocol@11 {
			reg = <0x11>;
			#power-domain-cells = <1>;
			status = "disabled";
		};

		scmi54_dvfs: protocol@13 {
			reg = <0x13>;
			#power-domain-cells = <1>;
			status = "disabled";
		};

		scmi54_sensor: protocol@15 {
			reg = <0x15>;
			#thermal-sensor-cells = <1>;
			status = "disabled";
		};

		scmi54_rst: protocol@16 {
			reg = <0x16>;
			#reset-cells = <1>;
			status = "disabled";
		};
	};

	scmi55: scmi@37 {
		compatible = "qcom,scmi-smc";
		arm,smc-id = <0xc6008012>;
		shmem = <&shmem55>;

		interrupts = <GIC_SPI 975 IRQ_TYPE_EDGE_RISING>;
		interrupt-names = "a2p";

		status = "disabled";

		#address-cells = <1>;
		#size-cells = <0>;

		scmi55_pd: protocol@11 {
			reg = <0x11>;
			#power-domain-cells = <1>;
			status = "disabled";
		};

		scmi55_dvfs: protocol@13 {
			reg = <0x13>;
			#power-domain-cells = <1>;
			status = "disabled";
		};

		scmi55_sensor: protocol@15 {
			reg = <0x15>;
			#thermal-sensor-cells = <1>;
			status = "disabled";
		};

		scmi55_rst: protocol@16 {
			reg = <0x16>;
			#reset-cells = <1>;
			status = "disabled";
		};
	};

	scmi56: scmi@38 {
		compatible = "qcom,scmi-smc";
		arm,smc-id = <0xc6008012>;
		shmem = <&shmem56>;

		interrupts = <GIC_SPI 976 IRQ_TYPE_EDGE_RISING>;
		interrupt-names = "a2p";

		status = "disabled";

		#address-cells = <1>;
		#size-cells = <0>;

		scmi56_pd: protocol@11 {
			reg = <0x11>;
			#power-domain-cells = <1>;
			status = "disabled";
		};

		scmi56_dvfs: protocol@13 {
			reg = <0x13>;
			#power-domain-cells = <1>;
			status = "disabled";
		};

		scmi56_sensor: protocol@15 {
			reg = <0x15>;
			#thermal-sensor-cells = <1>;
			status = "disabled";
		};

		scmi56_rst: protocol@16 {
			reg = <0x16>;
			#reset-cells = <1>;
			status = "disabled";
		};
	};

	scmi57: scmi@39 {
		compatible = "qcom,scmi-smc";
		arm,smc-id = <0xc6008012>;
		shmem = <&shmem57>;

		interrupts = <GIC_SPI 977 IRQ_TYPE_EDGE_RISING>;
		interrupt-names = "a2p";

		status = "disabled";

		#address-cells = <1>;
		#size-cells = <0>;

		scmi57_pd: protocol@11 {
			reg = <0x11>;
			#power-domain-cells = <1>;
			status = "disabled";
		};

		scmi57_dvfs: protocol@13 {
			reg = <0x13>;
			#power-domain-cells = <1>;
			status = "disabled";
		};

		scmi57_sensor: protocol@15 {
			reg = <0x15>;
			#thermal-sensor-cells = <1>;
			status = "disabled";
		};

		scmi57_rst: protocol@16 {
			reg = <0x16>;
			#reset-cells = <1>;
			status = "disabled";
		};
	};

	scmi58: scmi@3a {
		compatible = "qcom,scmi-smc";
		arm,smc-id = <0xc6008012>;
		shmem = <&shmem58>;

		interrupts = <GIC_SPI 978 IRQ_TYPE_EDGE_RISING>;
		interrupt-names = "a2p";

		status = "disabled";

		#address-cells = <1>;
		#size-cells = <0>;

		scmi58_pd: protocol@11 {
			reg = <0x11>;
			#power-domain-cells = <1>;
			status = "disabled";
		};

		scmi58_dvfs: protocol@13 {
			reg = <0x13>;
			#power-domain-cells = <1>;
			status = "disabled";
		};

		scmi58_sensor: protocol@15 {
			reg = <0x15>;
			#thermal-sensor-cells = <1>;
			status = "disabled";
		};

		scmi58_rst: protocol@16 {
			reg = <0x16>;
			#reset-cells = <1>;
			status = "disabled";
		};
	};

	scmi59: scmi@3b {
		compatible = "qcom,scmi-smc";
		arm,smc-id = <0xc6008012>;
		shmem = <&shmem59>;

		interrupts = <GIC_SPI 979 IRQ_TYPE_EDGE_RISING>;
		interrupt-names = "a2p";

		status = "disabled";

		#address-cells = <1>;
		#size-cells = <0>;

		scmi59_pd: protocol@11 {
			reg = <0x11>;
			#power-domain-cells = <1>;
			status = "disabled";
		};

		scmi59_dvfs: protocol@13 {
			reg = <0x13>;
			#power-domain-cells = <1>;
			status = "disabled";
		};

		scmi59_sensor: protocol@15 {
			reg = <0x15>;
			#thermal-sensor-cells = <1>;
			status = "disabled";
		};

		scmi59_rst: protocol@16 {
			reg = <0x16>;
			#reset-cells = <1>;
			status = "disabled";
		};
	};

	scmi60: scmi@3c {
		compatible = "qcom,scmi-smc";
		arm,smc-id = <0xc6008012>;
		shmem = <&shmem60>;

		interrupts = <GIC_SPI 980 IRQ_TYPE_EDGE_RISING>;
		interrupt-names = "a2p";

		status = "disabled";

		#address-cells = <1>;
		#size-cells = <0>;

		scmi60_pd: protocol@11 {
			reg = <0x11>;
			#power-domain-cells = <1>;
			status = "disabled";
		};

		scmi60_dvfs: protocol@13 {
			reg = <0x13>;
			#power-domain-cells = <1>;
			status = "disabled";
		};

		scmi60_sensor: protocol@15 {
			reg = <0x15>;
			#thermal-sensor-cells = <1>;
			status = "disabled";
		};

		scmi60_rst: protocol@16 {
			reg = <0x16>;
			#reset-cells = <1>;
			status = "disabled";
		};
	};

	scmi61: scmi@3d {
		compatible = "qcom,scmi-smc";
		arm,smc-id = <0xc6008012>;
		shmem = <&shmem61>;

		interrupts = <GIC_SPI 981 IRQ_TYPE_EDGE_RISING>;
		interrupt-names = "a2p";

		status = "disabled";

		#address-cells = <1>;
		#size-cells = <0>;

		scmi61_pd: protocol@11 {
			reg = <0x11>;
			#power-domain-cells = <1>;
			status = "disabled";
		};

		scmi61_dvfs: protocol@13 {
			reg = <0x13>;
			#power-domain-cells = <1>;
			status = "disabled";
		};

		scmi61_sensor: protocol@15 {
			reg = <0x15>;
			#thermal-sensor-cells = <1>;
			status = "disabled";
		};

		scmi61_rst: protocol@16 {
			reg = <0x16>;
			#reset-cells = <1>;
			status = "disabled";
		};
	};

	scmi62: scmi@3e {
		compatible = "qcom,scmi-smc";
		arm,smc-id = <0xc6008012>;
		shmem = <&shmem62>;

		interrupts = <GIC_SPI 982 IRQ_TYPE_EDGE_RISING>;
		interrupt-names = "a2p";

		status = "disabled";

		#address-cells = <1>;
		#size-cells = <0>;

		scmi62_pd: protocol@11 {
			reg = <0x11>;
			#power-domain-cells = <1>;
			status = "disabled";
		};

		scmi62_dvfs: protocol@13 {
			reg = <0x13>;
			#power-domain-cells = <1>;
			status = "disabled";
		};

		scmi62_sensor: protocol@15 {
			reg = <0x15>;
			#thermal-sensor-cells = <1>;
			status = "disabled";
		};

		scmi62_rst: protocol@16 {
			reg = <0x16>;
			#reset-cells = <1>;
			status = "disabled";
		};
	};

	scmi63: scmi@3f {
		compatible = "qcom,scmi-smc";
		arm,smc-id = <0xc6008012>;
		shmem = <&shmem63>;

		interrupts = <GIC_SPI 983 IRQ_TYPE_EDGE_RISING>;
		interrupt-names = "a2p";

		status = "disabled";

		#address-cells = <1>;
		#size-cells = <0>;

		scmi63_pd: protocol@11 {
			reg = <0x11>;
			#power-domain-cells = <1>;
			status = "disabled";
		};

		scmi63_dvfs: protocol@13 {
			reg = <0x13>;
			#power-domain-cells = <1>;
			status = "disabled";
		};

		scmi63_sensor: protocol@15 {
			reg = <0x15>;
			#thermal-sensor-cells = <1>;
			status = "disabled";
		};

		scmi63_rst: protocol@16 {
			reg = <0x16>;
			#reset-cells = <1>;
			status = "disabled";
		};
	};
};
